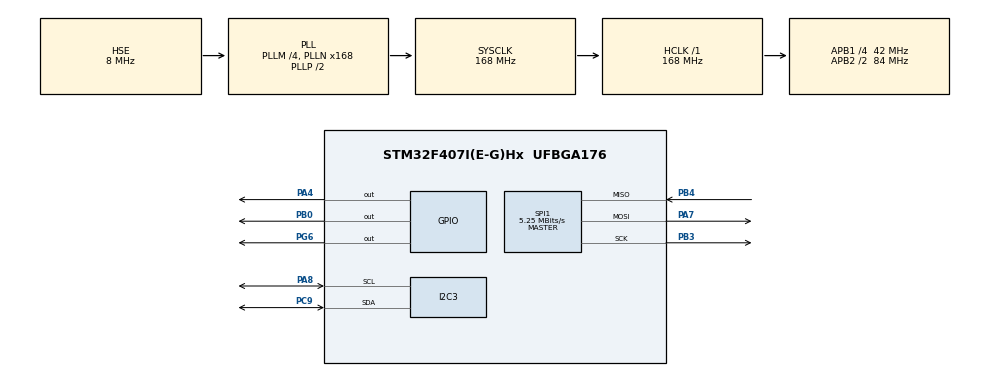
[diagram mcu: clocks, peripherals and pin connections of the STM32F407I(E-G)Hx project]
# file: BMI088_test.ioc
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I2C3.I2C_Mode=I2C_Fast
Mcu.Family=STM32F4
Mcu.Name=STM32F407I(E-G)Hx
Mcu.Package=UFBGA176
NVIC.PriorityGroup=NVIC_PRIORITYGROUP_4
PA13.Mode=Serial_Wire
PA13.Signal=SYS_JTMS-SWDIO
PA14.Mode=Serial_Wire
PA14.Signal=SYS_JTCK-SWCLK
PA4.GPIO_PuPd=GPIO_PULLUP
PA4.PinState=GPIO_PIN_SET
PA4.Signal=GPIO_Output
PA7.Mode=Full_Duplex_Master
PA7.Signal=SPI1_MOSI
PA8.Mode=I2C
PA8.Signal=I2C3_SCL
PB0.PinState=GPIO_PIN_SET
PB0.Signal=GPIO_Output
PB3.Mode=Full_Duplex_Master
PB3.Signal=SPI1_SCK
PB4.Mode=Full_Duplex_Master
PB4.Signal=SPI1_MISO
PC14-OSC32_IN.Mode=LSE-External-Oscillator
PC14-OSC32_IN.Signal=RCC_OSC32_IN
PC15-OSC32_OUT.Mode=LSE-External-Oscillator
PC15-OSC32_OUT.Signal=RCC_OSC32_OUT
PC9.Mode=I2C
PC9.Signal=I2C3_SDA
PG6.GPIO_PuPd=GPIO_PULLUP
PG6.GPIO_Speed=GPIO_SPEED_FREQ_MEDIUM
PG6.PinState=GPIO_PIN_SET
PG6.Signal=GPIO_Output
PH0-OSC_IN.Mode=HSE-External-Oscillator
PH0-OSC_IN.Signal=RCC_OSC_IN
PH1-OSC_OUT.Mode=HSE-External-Oscillator
PH1-OSC_OUT.Signal=RCC_OSC_OUT
ProjectManager.HeapSize=0x200
ProjectManager.StackSize=0x400
ProjectManager.TargetToolchain=MDK-ARM V5.32
RCC.48MHZClocksFreq_Value=84000000
RCC.AHBFreq_Value=168000000
RCC.APB1CLKDivider=RCC_HCLK_DIV4
RCC.APB1Freq_Value=42000000
RCC.APB1TimFreq_Value=84000000
RCC.APB2CLKDivider=RCC_HCLK_DIV2
RCC.APB2Freq_Value=84000000
RCC.APB2TimFreq_Value=168000000
RCC.CortexFreq_Value=168000000
RCC.HCLKFreq_Value=168000000
RCC.HSE_VALUE=8000000
RCC.HSI_VALUE=16000000
RCC.PLLM=4
RCC.PLLN=168
RCC.PLLSourceVirtual=RCC_PLLSOURCE_HSE
RCC.SYSCLKFreq_VALUE=168000000
RCC.SYSCLKSource=RCC_SYSCLKSOURCE_PLLCLK
RCC.VCOOutputFreq_Value=336000000
SPI1.BaudRatePrescaler=SPI_BAUDRATEPRESCALER_16
SPI1.CalculateBaudRate=5.25 MBits/s
SPI1.Direction=SPI_DIRECTION_2LINES
SPI1.Mode=SPI_MODE_MASTER
SPI1.VirtualType=VM_MASTER
board=custom

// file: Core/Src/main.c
/* USER CODE BEGIN Header */
/**
  ******************************************************************************
  * @file           : main.c
  * @brief          : Main program body
  ******************************************************************************
  * @attention
  *
  * Copyright (c) 2024 STMicroelectronics.
  * All rights reserved.
  *
  * This software is licensed under terms that can be found in the LICENSE file
  * in the root directory of this software component.
  * If no LICENSE file comes with this software, it is provided AS-IS.
  *
  ******************************************************************************
  */
/* USER CODE END Header */
#include "main.h"
#include "i2c.h"
#include "spi.h"
#include "gpio.h"

/* USER CODE BEGIN Includes */
#include "bmi088.h"
#include <math.h>
#include "bmi088reg.h"
//#include "ZiTai-jiesuan.h"
#include "MahonyAHRS.h"
#include "ist8310.h"
/* USER CODE END Includes */

void SystemClock_Config(void);

/* USER CODE BEGIN 0 */
  acc_raw_data_t acc_data;
  gyro_raw_data_t gyro_raw_data;
  ist8310_raw_data_t ist8310_raw_data;
  zitai_angle zitai;
/* USER CODE END 0 */

int main(void)
{

  /* MCU Configuration--------------------------------------------------------*/

  /* Reset of all peripherals, Initializes the Flash interface and the Systick. */
  HAL_Init();

  /* Configure the system clock */
  SystemClock_Config();

  /* Initialize all configured peripherals */
  MX_GPIO_Init();
  MX_SPI1_Init();
  MX_I2C3_Init();
  /* USER CODE BEGIN 2 */
  BMI088_CONF_INIT();
  IST8310_INIT();

  /* USER CODE END 2 */

  /* Infinite loop */
  while (1)
  {

    /* USER CODE BEGIN 3 */
//	  ReadAccData(&acc_data);
//	  ReadGyroData(&gyro_raw_data);
	  Read_Sensors(&acc_data, &gyro_raw_data,&ist8310_raw_data);
	  Calculate_Angles(&zitai.roll, &zitai.pitch, &zitai.yaw);
    }

  /* USER CODE END 3 */
}

void SystemClock_Config(void)
{
  RCC_OscInitTypeDef RCC_OscInitStruct = {0};
  RCC_ClkInitTypeDef RCC_ClkInitStruct = {0};

  /** Configure the main internal regulator output voltage
  */
  __HAL_RCC_PWR_CLK_ENABLE();
  __HAL_PWR_VOLTAGESCALING_CONFIG(PWR_REGULATOR_VOLTAGE_SCALE1);

  /** Initializes the RCC Oscillators according to the specified parameters
  * in the RCC_OscInitTypeDef structure.
  */
  RCC_OscInitStruct.OscillatorType = RCC_OSCILLATORTYPE_HSE;
  RCC_OscInitStruct.HSEState = RCC_HSE_ON;
  RCC_OscInitStruct.PLL.PLLState = RCC_PLL_ON;
  RCC_OscInitStruct.PLL.PLLSource = RCC_PLLSOURCE_HSE;
  RCC_OscInitStruct.PLL.PLLM = 4;
  RCC_OscInitStruct.PLL.PLLN = 168;
  RCC_OscInitStruct.PLL.PLLP = RCC_PLLP_DIV2;
  RCC_OscInitStruct.PLL.PLLQ = 4;
  if (HAL_RCC_OscConfig(&RCC_OscInitStruct) != HAL_OK)
  {
    Error_Handler();
  }

  /** Initializes the CPU, AHB and APB buses clocks
  */
  RCC_ClkInitStruct.ClockType = RCC_CLOCKTYPE_HCLK|RCC_CLOCKTYPE_SYSCLK
                              |RCC_CLOCKTYPE_PCLK1|RCC_CLOCKTYPE_PCLK2;
  RCC_ClkInitStruct.SYSCLKSource = RCC_SYSCLKSOURCE_PLLCLK;
  RCC_ClkInitStruct.AHBCLKDivider = RCC_SYSCLK_DIV1;
  RCC_ClkInitStruct.APB1CLKDivider = RCC_HCLK_DIV4;
  RCC_ClkInitStruct.APB2CLKDivider = RCC_HCLK_DIV2;

  if (HAL_RCC_ClockConfig(&RCC_ClkInitStruct, FLASH_LATENCY_5) != HAL_OK)
  {
    Error_Handler();
  }
}

void Error_Handler(void)
{
  __disable_irq();
  while (1)
  {
  }
}
